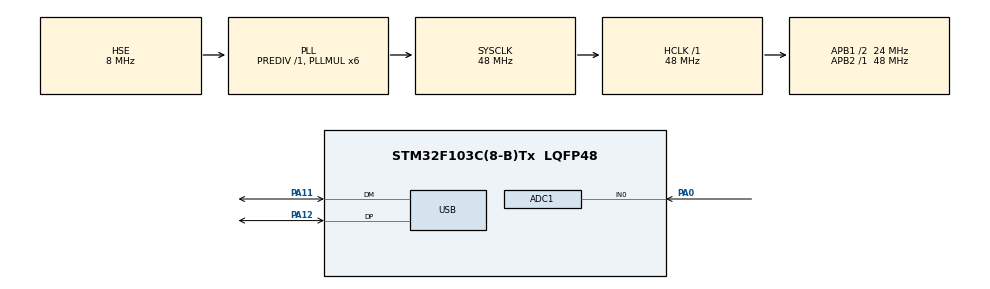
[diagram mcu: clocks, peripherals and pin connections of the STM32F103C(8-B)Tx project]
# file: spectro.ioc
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ADC1.ContinuousConvMode=ENABLE
ADC1.ExternalTrigConv=ADC_SOFTWARE_START
ADC1.ExternalTrigConvEdgeChoice=NONE
ADC1.NbrOfConversion=1
ADC1.NbrOfConversionFlag=1
ADC1.SamplingTime-0\#ChannelRegularConversion=ADC_SAMPLETIME_239CYCLES_5
ADC1.master=1
Dma.ADC1.0.Direction=DMA_PERIPH_TO_MEMORY
Dma.ADC1.0.Instance=DMA1_Channel1
Dma.ADC1.0.MemDataAlignment=DMA_MDATAALIGN_HALFWORD
Dma.ADC1.0.MemInc=DMA_MINC_ENABLE
Dma.ADC1.0.Mode=DMA_NORMAL
Dma.ADC1.0.PeriphDataAlignment=DMA_PDATAALIGN_HALFWORD
Dma.ADC1.0.PeriphInc=DMA_PINC_DISABLE
Dma.ADC1.0.Priority=DMA_PRIORITY_LOW
Dma.Request0=ADC1
Mcu.Family=STM32F1
Mcu.Name=STM32F103C(8-B)Tx
Mcu.Package=LQFP48
NVIC.DMA1_Channel1_IRQn=true\:0\:0\:false
NVIC.PriorityGroup=NVIC_PRIORITYGROUP_4
NVIC.USB_LP_CAN1_RX0_IRQn=true\:0\:0\:false
PA0-WKUP.Signal=ADCx_IN0
PA11.Mode=Device
PA11.Signal=USB_DM
PA12.Mode=Device
PA12.Signal=USB_DP
PA13.Mode=Serial_Wire
PA13.Signal=SYS_JTMS-SWDIO
PA14.Mode=Serial_Wire
PA14.Signal=SYS_JTCK-SWCLK
PC14-OSC32_IN.Mode=LSE-External-Oscillator
PC14-OSC32_IN.Signal=RCC_OSC32_IN
PC15-OSC32_OUT.Mode=LSE-External-Oscillator
PC15-OSC32_OUT.Signal=RCC_OSC32_OUT
PD0-OSC_IN.Mode=HSE-External-Oscillator
PD0-OSC_IN.Signal=RCC_OSC_IN
PD1-OSC_OUT.Mode=HSE-External-Oscillator
PD1-OSC_OUT.Signal=RCC_OSC_OUT
ProjectManager.TargetToolchain=MDK-ARM V4
RCC.ADCPresc=RCC_ADCPCLK2_DIV4
RCC.AHBFreq_Value=48000000
RCC.APB1CLKDivider=RCC_HCLK_DIV2
RCC.APB1Freq_Value=24000000
RCC.APB1TimFreq_Value=48000000
RCC.APB2Freq_Value=48000000
RCC.APB2TimFreq_Value=48000000
RCC.HCLKFreq_Value=48000000
RCC.HSIState=RCC_HSI_ON
RCC.PLLMUL=RCC_PLL_MUL6
RCC.SYSCLKFreq_VALUE=48000000
RCC.SYSCLKSource=RCC_SYSCLKSOURCE_PLLCLK
RCC.USBFreq_Value=48000000
SH.ADCx_IN0.0=ADC1_IN0,IN0
USB_DEVICE.USBD_HandleTypeDef=hUsbDeviceFS
USB_DEVICE.VirtualMode=Cdc
USB_DEVICE.VirtualModeFS=Cdc_FS
VP_USB_DEVICE_VS_USB_DEVICE_CDC_FS.Mode=CDC_FS
board=custom

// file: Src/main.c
/**
  ******************************************************************************
  * File Name          : main.c
  * Description        : Main program body
  ******************************************************************************
  *
  * COPYRIGHT(c) 2015 STMicroelectronics
  *
  * Redistribution and use in source and binary forms, with or without modification,
  * are permitted provided that the following conditions are met:
  *   1. Redistributions of source code must retain the above copyright notice,
  *      this list of conditions and the following disclaimer.
  *   2. Redistributions in binary form must reproduce the above copyright notice,
  *      this list of conditions and the following disclaimer in the documentation
  *      and/or other materials provided with the distribution.
  *   3. Neither the name of STMicroelectronics nor the names of its contributors
  *      may be used to endorse or promote products derived from this software
  *      without specific prior written permission.
  *
  * THIS SOFTWARE IS PROVIDED BY THE COPYRIGHT HOLDERS AND CONTRIBUTORS "AS IS"
  * AND ANY EXPRESS OR IMPLIED WARRANTIES, INCLUDING, BUT NOT LIMITED TO, THE
  * IMPLIED WARRANTIES OF MERCHANTABILITY AND FITNESS FOR A PARTICULAR PURPOSE ARE
  * DISCLAIMED. IN NO EVENT SHALL THE COPYRIGHT HOLDER OR CONTRIBUTORS BE LIABLE
  * FOR ANY DIRECT, INDIRECT, INCIDENTAL, SPECIAL, EXEMPLARY, OR CONSEQUENTIAL
  * DAMAGES (INCLUDING, BUT NOT LIMITED TO, PROCUREMENT OF SUBSTITUTE GOODS OR
  * SERVICES; LOSS OF USE, DATA, OR PROFITS; OR BUSINESS INTERRUPTION) HOWEVER
  * CAUSED AND ON ANY THEORY OF LIABILITY, WHETHER IN CONTRACT, STRICT LIABILITY,
  * OR TORT (INCLUDING NEGLIGENCE OR OTHERWISE) ARISING IN ANY WAY OUT OF THE USE
  * OF THIS SOFTWARE, EVEN IF ADVISED OF THE POSSIBILITY OF SUCH DAMAGE.
  *
  ******************************************************************************
  */

#include "stm32f1xx_hal.h"
#include "usb_device.h"

/* USER CODE BEGIN Includes */
#include "usbd_cdc_if.h"
/* USER CODE END Includes */

ADC_HandleTypeDef hadc1;
DMA_HandleTypeDef hdma_adc1;

/* USER CODE BEGIN PV */
char buf[25];
uint16_t adc_res[800];
int8_t scale = 0;
/* USER CODE END PV */

void SystemClock_Config(void);
static void MX_GPIO_Init(void);
static void MX_DMA_Init(void);
static void MX_ADC1_Init(void);
static void ADC_set_speed(int scale);

int main(void)
{

  /* MCU Configuration----------------------------------------------------------*/

  /* Reset of all peripherals, Initializes the Flash interface and the Systick. */
  HAL_Init();

  /* Configure the system clock */
  SystemClock_Config();

  /* Initialize all configured peripherals */
  MX_GPIO_Init();
  MX_DMA_Init();
  MX_ADC1_Init();
  MX_USB_DEVICE_Init();

  /* USER CODE BEGIN 2 */

		HAL_Delay(1000);
  /* USER CODE END 2 */

  /* Infinite loop */
  while (1)
  {

  /* USER CODE BEGIN 3 */

		HAL_ADC_Start(&hadc1);
		HAL_ADC_Start_DMA(&hadc1,(uint32_t*)adc_res,800);

		sprintf(buf,"frame\n");
		CDC_Transmit_FS((uint8_t*)buf, strlen(buf));

//		uint16_t tmp = HAL_ADC_GetValue(&hadc1);
		HAL_DMA_PollForTransfer(&hdma_adc1,HAL_DMA_FULL_TRANSFER,100);
		//HAL_ADC_Stop_DMA(&hadc1);
		//HAL_ADC_Stop(&hadc1);

		for(int i = 0; i < 800; i++) {
				sprintf(buf,"%i\n", adc_res[i]);
				CDC_Transmit_FS((uint8_t*)buf, strlen(buf));
				HAL_Delay(1);
			}
			char c = ' ';
			VCP_read(&c, 1);
			switch(c){
			case '+': { if (scale == 7) scale = 0; else scale++;
				HAL_ADC_Stop(&hadc1);
				ADC_set_speed(scale);
				sprintf(buf,"state %d\n", scale);
				CDC_Transmit_FS((uint8_t*)buf, strlen(buf));
				break;}
			case '-': {if (scale == 0) scale = 7; else scale--;
				HAL_ADC_Stop(&hadc1);
				ADC_set_speed(scale);
				sprintf(buf,"state %d\n", scale);
				CDC_Transmit_FS((uint8_t*)buf, strlen(buf));
				break;}
			default: break;
			}

}
  /* USER CODE END 3 */

}

/** System Clock Configuration
*/
void SystemClock_Config(void)
{

  RCC_OscInitTypeDef RCC_OscInitStruct;
  RCC_ClkInitTypeDef RCC_ClkInitStruct;
  RCC_PeriphCLKInitTypeDef PeriphClkInit;

  RCC_OscInitStruct.OscillatorType = RCC_OSCILLATORTYPE_HSE;
  RCC_OscInitStruct.HSEState = RCC_HSE_ON;
  RCC_OscInitStruct.HSEPredivValue = RCC_HSE_PREDIV_DIV1;
  RCC_OscInitStruct.PLL.PLLState = RCC_PLL_ON;
  RCC_OscInitStruct.PLL.PLLSource = RCC_PLLSOURCE_HSE;
  RCC_OscInitStruct.PLL.PLLMUL = RCC_PLL_MUL6;
  HAL_RCC_OscConfig(&RCC_OscInitStruct);

  RCC_ClkInitStruct.ClockType = RCC_CLOCKTYPE_SYSCLK|RCC_CLOCKTYPE_PCLK1;
  RCC_ClkInitStruct.SYSCLKSource = RCC_SYSCLKSOURCE_PLLCLK;
  RCC_ClkInitStruct.AHBCLKDivider = RCC_SYSCLK_DIV1;
  RCC_ClkInitStruct.APB1CLKDivider = RCC_HCLK_DIV2;
  RCC_ClkInitStruct.APB2CLKDivider = RCC_HCLK_DIV1;
  HAL_RCC_ClockConfig(&RCC_ClkInitStruct, FLASH_LATENCY_1);

  PeriphClkInit.PeriphClockSelection = RCC_PERIPHCLK_ADC|RCC_PERIPHCLK_USB;
  PeriphClkInit.AdcClockSelection = RCC_ADCPCLK2_DIV4;
  PeriphClkInit.UsbClockSelection = RCC_USBPLLCLK_DIV1;
  HAL_RCCEx_PeriphCLKConfig(&PeriphClkInit);

  HAL_SYSTICK_Config(HAL_RCC_GetHCLKFreq()/1000);

  HAL_SYSTICK_CLKSourceConfig(SYSTICK_CLKSOURCE_HCLK);

}

/* ADC1 init function */
void MX_ADC1_Init(void)
{

    /**Common config
    */
  hadc1.Instance = ADC1;
  hadc1.Init.ScanConvMode = ADC_SCAN_DISABLE;
  hadc1.Init.ContinuousConvMode = ENABLE;
  hadc1.Init.DiscontinuousConvMode = DISABLE;
  hadc1.Init.ExternalTrigConv = ADC_SOFTWARE_START;
  hadc1.Init.DataAlign = ADC_DATAALIGN_RIGHT;
  hadc1.Init.NbrOfConversion = 1;
  HAL_ADC_Init(&hadc1);

    /**Configure Regular Channel
    */
	  ADC_ChannelConfTypeDef sConfig;
  sConfig.Channel = ADC_CHANNEL_0;
  sConfig.Rank = 1;
  sConfig.SamplingTime = ADC_SAMPLETIME_239CYCLES_5;
  HAL_ADC_ConfigChannel(&hadc1, &sConfig);

}

void MX_DMA_Init(void)
{
  /* DMA controller clock enable */
  __HAL_RCC_DMA1_CLK_ENABLE();

  /* DMA interrupt init */
  HAL_NVIC_SetPriority(DMA1_Channel1_IRQn, 0, 0);
  HAL_NVIC_EnableIRQ(DMA1_Channel1_IRQn);

}

/** Configure pins as
        * Analog
        * Input
        * Output
        * EVENT_OUT
        * EXTI
*/
void MX_GPIO_Init(void)
{

  /* GPIO Ports Clock Enable */
  __GPIOC_CLK_ENABLE();
  __GPIOD_CLK_ENABLE();
  __GPIOA_CLK_ENABLE();

}

/* USER CODE BEGIN 4 */

static void ADC_set_speed(int s){

	  hadc1.Instance = ADC1;
  hadc1.Init.ScanConvMode = ADC_SCAN_DISABLE;
  hadc1.Init.ContinuousConvMode = ENABLE;
  hadc1.Init.DiscontinuousConvMode = DISABLE;
  hadc1.Init.ExternalTrigConv = ADC_SOFTWARE_START;
  hadc1.Init.DataAlign = ADC_DATAALIGN_RIGHT;
  hadc1.Init.NbrOfConversion = 1;
  HAL_ADC_Init(&hadc1);

	  ADC_ChannelConfTypeDef sConfig;
  sConfig.Channel = ADC_CHANNEL_0;
  sConfig.Rank = 1;

	switch(s){
	case 0 : sConfig.SamplingTime = ADC_SAMPLETIME_1CYCLE_5   ;break;
	case 1 : sConfig.SamplingTime = ADC_SAMPLETIME_7CYCLES_5  ;break;
	case 2 : sConfig.SamplingTime = ADC_SAMPLETIME_13CYCLES_5 ;break;
	case 3 : sConfig.SamplingTime = ADC_SAMPLETIME_28CYCLES_5 ;break;
	case 4 : sConfig.SamplingTime = ADC_SAMPLETIME_41CYCLES_5 ;break;
	case 5 : sConfig.SamplingTime = ADC_SAMPLETIME_55CYCLES_5 ;break;
	case 6 : sConfig.SamplingTime = ADC_SAMPLETIME_71CYCLES_5 ;break;
	case 7 : sConfig.SamplingTime = ADC_SAMPLETIME_239CYCLES_5;break;
	default: sConfig.SamplingTime = ADC_SAMPLETIME_239CYCLES_5;break;
	}

  HAL_ADC_ConfigChannel(&hadc1, &sConfig);
}

/* USER CODE END 4 */

/************************ (C) COPYRIGHT STMicroelectronics *****END OF FILE****/
